VERSION 0

BO_ 15 RemoteControl: 8
  SG_ l_top : 0|1@1+ (1,0) [0|1] ""
  SG_ l_bottom : 1|1@1+ (1,0) [0|1] ""
  SG_ l_right : 2|1@1+ (1,0) [0|1] ""
  SG_ l_left : 3|1@1+ (1,0) [0|1] ""
  SG_ r_top : 4|1@1+ (1,0) [0|1] ""
  SG_ r_bottom : 5|1@1+ (1,0) [0|1] ""
  SG_ r_right : 6|1@1+ (1,0) [0|1] ""
  SG_ r_left : 7|1@1+ (1,0) [0|1] ""
  SG_ l_shoulder : 8|1@1+ (1,0) [0|1] ""
  SG_ r_shoulder : 9|1@1+ (1,0) [0|1] ""
  SG_ e_stop : 10|1@1+ (1,0) [0|1] ""
  SG_ left_trigger : 16|8@1+ (1,0) [0|255] ""
  SG_ right_trigger : 24|8@1+ (1,0) [0|255] ""
  SG_ thumb_left_x : 32|8@1+ (1,0) [0|255] ""
  SG_ thumb_left_y : 40|8@1+ (1,0) [0|255] ""
  SG_ thumb_right_x : 48|8@1+ (1,0) [0|255] ""
  SG_ thumb_right_y : 56|8@1+ (1,0) [0|255] ""

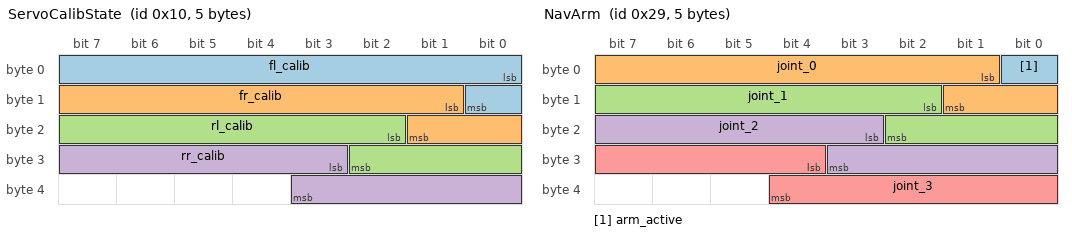
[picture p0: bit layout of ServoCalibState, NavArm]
BO_ 16 ServoCalibState: 5
  SG_ fl_calib : 0|9@1+ (1,0) [0|511] "°"
  SG_ fr_calib : 9|9@1+ (1,0) [0|511] "°"
  SG_ rl_calib : 18|9@1+ (1,0) [0|511] "°"
  SG_ rr_calib : 27|9@1+ (1,0) [0|511] "°"

BO_ 30 RaspiState: 21
  SG_ rpi_3v7_wl_sw_a : 0|10@1+ (0.009765625,0) [0|10] "A"
  SG_ rpi_3v3_sys_a : 10|10@1+ (0.009765625,0) [0|10] "A"
  SG_ rpi_1v8_sys_a : 20|10@1+ (0.009765625,0) [0|10] "A"
  SG_ rpi_1v1_sys_a : 30|10@1+ (0.009765625,0) [0|10] "A"
  SG_ rpi_0v8_sw_a : 40|10@1+ (0.009765625,0) [0|10] "A"
  SG_ vdd_core_a : 50|10@1+ (0.009765625,0) [0|10] "A"
  SG_ rpi_3v7_wl_sw_v : 60|8@1+ (0.01953125,0) [0|5] "V"
  SG_ rpi_3v3_sys_v :  68|8@1+ (0.01953125,0) [0|5] "V"
  SG_ rpi_1v8_sys_v :  76|8@1+ (0.01953125,0) [0|5] "V"
  SG_ rpi_1v1_sys_v :  84|8@1+ (0.01953125,0) [0|5] "V"
  SG_ rpi_0v8_sw_v :  92|8@1+ (0.01953125,0) [0|5] "V"
  SG_ vdd_core_v :  100|8@1+ (0.01953125,0) [0|5] "V"
  SG_ rpi_ext5v_v :  108|8@1+ (0.0234375,0) [0|6] "V"
  SG_ rpi_temp : 116|8@1+ (0.3125,20) [20|100] "°C"
  SG_ rpi_cpu : 124|8@1+ (0.390625,0) [0|100] "%"
  SG_ rpi_mem : 132|8@1+ (0.390625,0) [0|100] "%"
  SG_ rpi_rssi : 140|8@1+ (0.78125,-150) [-150|50] "dBm"
  SG_ rpi_ina_voltage : 148|10@1+ (0.01953125,0) [0|20] "V"
  SG_ rpi_ina_current : 158|10@1+ (0.01953125,0) [0|20] "A"

BO_ 40 NavLocomotion: 10
  SG_ odometry : 0|8@1+ (0.78125,-100) [-100|100] "m"
  SG_ motor_fl_target : 8|12@1+ (4.8828125,-10000) [-10000|10000] ""
  SG_ motor_fr_target : 20|12@1+ (4.8828125,-10000) [-10000|10000] ""
  SG_ motor_ml_target : 32|12@1+ (4.8828125,-10000) [-10000|10000] ""
  SG_ motor_mr_target : 44|12@1+ (4.8828125,-10000) [-10000|10000] ""
  SG_ motor_rl_target : 56|12@1+ (4.8828125,-10000) [-10000|10000] ""
  SG_ motor_rr_target : 68|12@1+ (4.8828125,-10000) [-10000|10000] ""

BO_ 41 NavArm: 5
  SG_ arm_active : 0|1@1+ (1,0) [0|1] ""
  SG_ joint_0 : 1|9@1+ (0.705,0) [0|360] "°"
  SG_ joint_1 : 10|9@1+ (0.705,0) [0|360] "°"
  SG_ joint_2 : 19|9@1+ (0.705,0) [0|360] "°"
  SG_ joint_3 : 28|9@1+ (0.705,0) [0|360] "°"

BO_ 70 ScienceWeight: 2
  SG_ scale_meas : 0|15@1+ (0.0152587890625,0) [0|500] "g"
  SG_ scale_valid : 15|1@1+ (1,0) [0|1] ""
